# STM32GBK1CBT6 register map
File version: 1.6
CPU: CM4 r0p1, little endian, MPU, FPU, 4 interrupt priority bits
Registers are 32-bit, read-write, reset 0x0 unless marked. A register's access mark holds for its fields unless they carry their own. Offsets are from the block's base; [hi:lo] are bit positions; {n}, {i} and the like mark numbered series; 'fields as' and 'values as' point back to an identical list.

## EXTI — External interrupt/event controller
Base 0x40010400
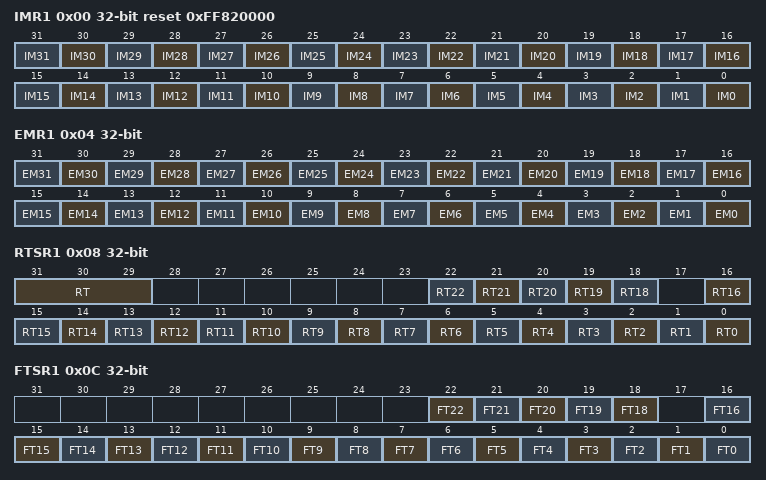
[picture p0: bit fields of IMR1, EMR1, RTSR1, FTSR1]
0x00 IMR1 reset 0xFF820000 — Interrupt mask register
  [n] IM{n} (n=0..31) — Interrupt Mask on line {n}
0x04 EMR1 — Event mask register
  [n] EM{n} (n=0..31) — Event Mask on line {n}
0x08 RTSR1 — Rising Trigger selection register
  [31:29] RT
  [n] RT{n} (n=18..22) — Rising trigger event configuration of line {n}
  [n] RT{n} (n=0..16) — Rising trigger event configuration of line {n}
0x0C FTSR1 — Falling Trigger selection register
  [n] FT{n} (n=18..22) — Falling trigger event configuration of line {n}
  [n] FT{n} (n=0..16) — Falling trigger event configuration of line {n}
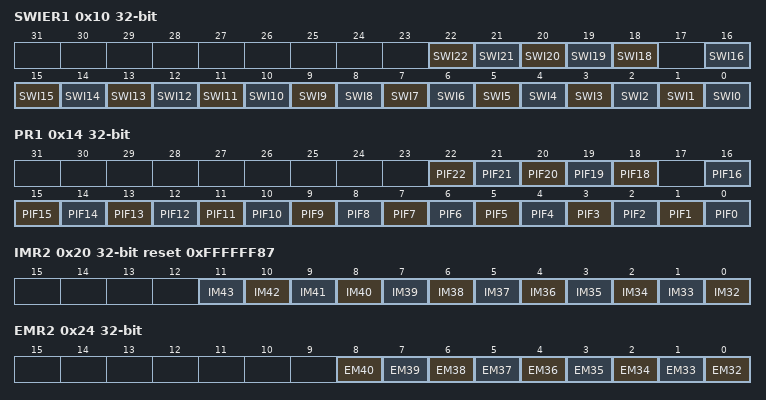
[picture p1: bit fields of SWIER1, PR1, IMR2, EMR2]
0x10 SWIER1 — Software interrupt event register
  [n] SWI{n} (n=18..22) — Software Interrupt on line {n}
  [n] SWI{n} (n=0..16) — Software Interrupt on line {n}
0x14 PR1 — Pending register
  [n] PIF{n} (n=18..22) — Pending bit {n}
  [n] PIF{n} (n=0..16) — Pending bit {n}
0x20 IMR2 reset 0xFFFFFF87 — Interrupt mask register
  [n-32] IM{n} (n=32..43) — Interrupt Mask on external/internal line {n}
0x24 EMR2 — Event mask register
  [n-32] EM{n} (n=32..40) — Event mask on external/internal line {n}
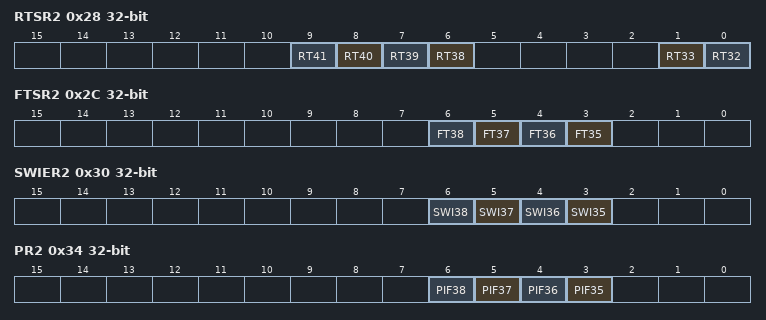
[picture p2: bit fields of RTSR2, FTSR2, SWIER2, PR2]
0x28 RTSR2 — Rising Trigger selection register
  [n-32] RT{n} (n=38..41) — Rising trigger event configuration bit of line {n}
  [1] RT33 — Rising trigger event configuration bit of line 32
  [0] RT32 — Rising trigger event configuration bit of line 32
0x2C FTSR2 — Falling Trigger selection register
  [n-32] FT{n} (n=35..38) — Falling trigger event configuration bit of line {n}
0x30 SWIER2 — Software interrupt event register
  [n-32] SWI{n} (n=35..38) — Software interrupt on line {n}
0x34 PR2 — Pending register
  [n-32] PIF{n} (n=35..38) — Pending interrupt flag on line {n}

## DMA1 — DMA controller
Base 0x40020000
Same registers: DMA2 0x40020400
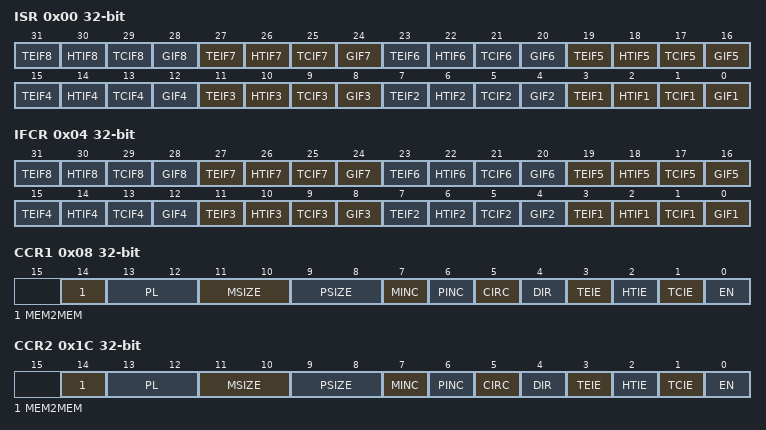
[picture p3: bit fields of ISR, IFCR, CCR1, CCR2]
0x00 ISR ro — interrupt status register
  [4n-1] TEIF{n} (n=1..8), [4n-2] HTIF{n} (n=1..8), [4n-3] TCIF{n} (n=1..8), [4n-4] GIF{n} (n=1..8)
0x04 IFCR wo — DMA interrupt flag clear register
  fields as ISR
0x08 CCR1 — DMA channel 1 configuration register
  [14] MEM2MEM
  [13:12] PL
  [11:10] MSIZE
  [9:8] PSIZE
  [7] MINC
  [6] PINC
  [5] CIRC
  [4] DIR
  [3] TEIE
  [2] HTIE
  [1] TCIE
  [0] EN — channel enable
0x0C CNDTR1 — channel x number of data to transfer register
  [15:0] NDT — Number of data items to transfer
0x10 CPAR1 — DMA channel x peripheral address register
  [31:0] PA — Peripheral address
{0x0+0x14*i} CMAR{i} (i=1..8) — DMA channel x memory address register
  [31:0] MA — Memory 1 address (used in case of Double buffer mode)
0x1C CCR2 — DMA channel 2 configuration register
  fields as CCR1
0x20 CNDTR2 — channel x number of data to transfer register
  [15:0] NDT — Number of data items to transfer
0x24 CPAR2 — DMA channel x peripheral address register
  [31:0] PA — Peripheral address
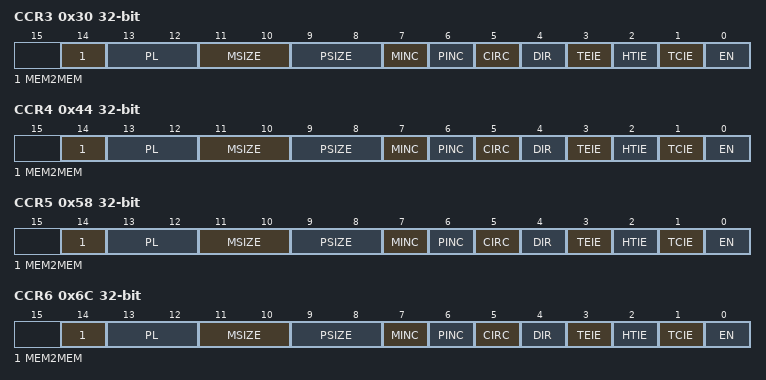
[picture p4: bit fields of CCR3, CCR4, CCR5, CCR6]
0x30 CCR3 — DMA channel 3 configuration register
  fields as CCR1
0x34 CNDTR3 — channel x number of data to transfer register
  [15:0] NDT — Number of data items to transfer
0x38 CPAR3 — DMA channel x peripheral address register
  [31:0] PA — Peripheral address
0x44 CCR4 — DMA channel 3 configuration register
  fields as CCR1
0x48 CNDTR4 — channel x number of data to transfer register
  [15:0] NDT — Number of data items to transfer
0x4C CPAR4 — DMA channel x peripheral address register
  [31:0] PA — Peripheral address
0x58 CCR5 — DMA channel 4 configuration register
  fields as CCR1
0x5C CNDTR5 — channel x number of data to transfer register
  [15:0] NDT — Number of data items to transfer
0x60 CPAR5 — DMA channel x peripheral address register
  [31:0] PA — Peripheral address
0x6C CCR6 — DMA channel 5 configuration register
  fields as CCR1
0x70 CNDTR6 — channel x number of data to transfer register
  [15:0] NDT — Number of data items to transfer
0x74 CPAR6 — DMA channel x peripheral address register
  [31:0] PA — Peripheral address
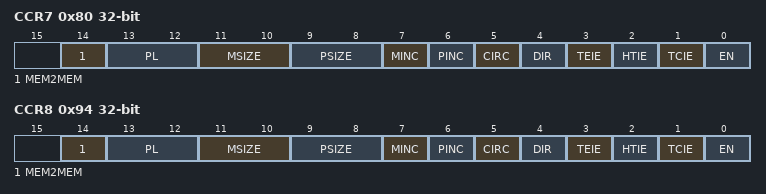
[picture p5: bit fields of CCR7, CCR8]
0x80 CCR7 — DMA channel 6 configuration register
  fields as CCR1
0x84 CNDTR7 — channel x number of data to transfer register
  [15:0] NDT — Number of data items to transfer
0x88 CPAR7 — DMA channel x peripheral address register
  [31:0] PA — Peripheral address
0x94 CCR8 — DMA channel 7 configuration register
  fields as CCR1
0x98 CNDTR8 — channel x number of data to transfer register
  [15:0] NDT — Number of data items to transfer
0x9C CPAR8 — DMA channel x peripheral address register
  [31:0] PA — Peripheral address
